# STM32F7x7 register map
File version: 1.4
CPU: CM7 r0p1, little endian, MPU, FPU, VTOR, 4 interrupt priority bits
Registers are 32-bit, read-write, reset 0x0 unless marked. A register's access mark holds for its fields unless they carry their own. Offsets are from the block's base; [hi:lo] are bit positions; lines under a group give offsets from that group; {n}, {i} and the like mark numbered series.

## DFSDM — Digital filter for sigma delta modulators
Base 0x40017400
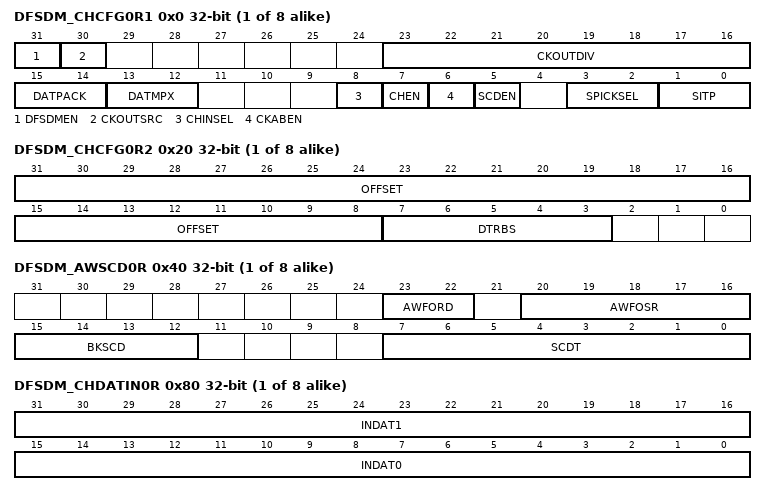
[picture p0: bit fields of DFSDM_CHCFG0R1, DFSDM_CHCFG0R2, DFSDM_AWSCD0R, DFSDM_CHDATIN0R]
{0x0+4i} DFSDM_CHCFG{i}R1 (i=0..7) — DFSDM channel configuration {i} register 1
  [31] DFSDMEN — Global enable for DFSDM interface
  [30] CKOUTSRC — Output serial clock source selection
  [23:16] CKOUTDIV — Output serial clock divider
  [15:14] DATPACK — Data packing mode in DFSDM_CHDATINyR register
  [13:12] DATMPX — Input data multiplexer for channel {i}
  [8] CHINSEL — Channel inputs selection
  [7] CHEN — Channel {i} enable
  [6] CKABEN — Clock absence detector enable on channel {i}
  [5] SCDEN — Short-circuit detector enable on channel {i}
  [3:2] SPICKSEL — SPI clock select for channel {i}
  [1:0] SITP — Serial interface type for channel {i}
{0x20+4i} DFSDM_CHCFG{i}R2 (i=0..7) — DFSDM channel configuration {i} register 2
  [31:8] OFFSET — 24-bit calibration offset for channel {i}
  [7:3] DTRBS — Data right bit-shift for channel {i}
{0x40+4i} DFSDM_AWSCD{i}R (i=0..7) — DFSDM analog watchdog and short-circuit detector register
  [23:22] AWFORD — Analog watchdog Sinc filter order on channel {i}
  [20:16] AWFOSR — Analog watchdog filter oversampling ratio (decimation rate) on channel {i}
  [15:12] BKSCD — Break signal assignment for short-circuit detector on channel {i}
  [7:0] SCDT — short-circuit detector threshold for channel {i}
{0x60+4i} DFSDM_CHWDAT{i}R ro (i=0..7) — DFSDM channel watchdog filter data register
  [15:0] WDATA — Input channel y watchdog data
{0x80+4i} DFSDM_CHDATIN{i}R (i=0..7) — DFSDM channel data input register
  [31:16] INDAT1 — Input data for channel {i+1}
  [15:0] INDAT0 — Input data for channel {i}
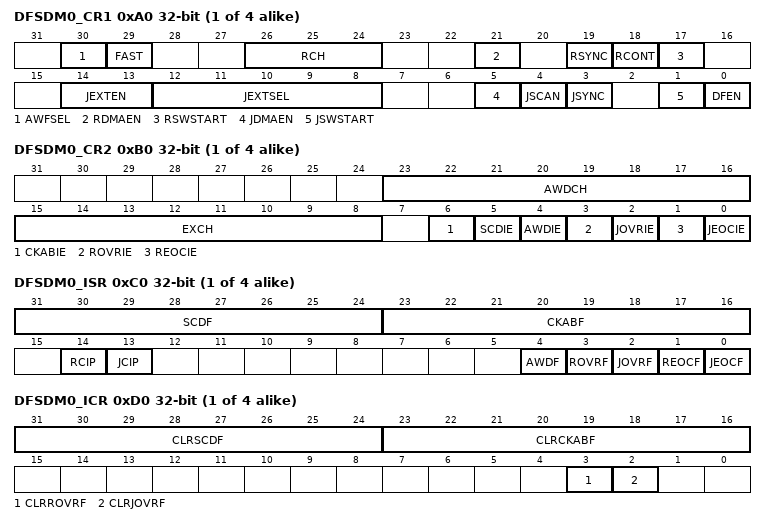
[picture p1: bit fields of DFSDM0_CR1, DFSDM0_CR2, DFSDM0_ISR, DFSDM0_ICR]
{0xA0+4i} DFSDM{i}_CR1 (i=0..3) — DFSDM control register 1
  [30] AWFSEL — Analog watchdog fast mode select
  [29] FAST — Fast conversion mode selection for regular conversions
  [26:24] RCH — Regular channel selection
  [21] RDMAEN — DMA channel enabled to read data for the regular conversion
  [19] RSYNC — Launch regular conversion synchronously with DFSDM0
  [18] RCONT — Continuous mode selection for regular conversions
  [17] RSWSTART — Software start of a conversion on the regular channel
  [14:13] JEXTEN — Trigger enable and trigger edge selection for injected conversions
  [12:8] JEXTSEL — Trigger signal selection for launching injected conversions
  [5] JDMAEN — DMA channel enabled to read data for the injected channel group
  [4] JSCAN — Scanning conversion mode for injected conversions
  [3] JSYNC — Launch an injected conversion synchronously with the DFSDM0 JSWSTART trigger
  [1] JSWSTART — Start a conversion of the injected group of channels
  [0] DFEN — DFSDM enable
{0xB0+4i} DFSDM{i}_CR2 (i=0..3) — DFSDM control register 2
  [23:16] AWDCH — Analog watchdog channel selection
  [15:8] EXCH — Extremes detector channel selection
  [6] CKABIE — Clock absence interrupt enable
  [5] SCDIE — Short-circuit detector interrupt enable
  [4] AWDIE — Analog watchdog interrupt enable
  [3] ROVRIE — Regular data overrun interrupt enable
  [2] JOVRIE — Injected data overrun interrupt enable
  [1] REOCIE — Regular end of conversion interrupt enable
  [0] JEOCIE — Injected end of conversion interrupt enable
{0xC0+4i} DFSDM{i}_ISR ro (i=0..3) — DFSDM interrupt and status register
  [31:24] SCDF — short-circuit detector flag
  [23:16] CKABF — Clock absence flag
  [14] RCIP — Regular conversion in progress status
  [13] JCIP — Injected conversion in progress status
  [4] AWDF — Analog watchdog
  [3] ROVRF — Regular conversion overrun flag
  [2] JOVRF — Injected conversion overrun flag
  [1] REOCF — End of regular conversion flag
  [0] JEOCF — End of injected conversion flag
{0xD0+4i} DFSDM{i}_ICR (i=0..3) — DFSDM interrupt flag clear register
  [31:24] CLRSCDF — Clear the short-circuit detector flag
  [23:16] CLRCKABF — Clear the clock absence flag
  [3] CLRROVRF — Clear the regular conversion overrun flag
  [2] CLRJOVRF — Clear the injected conversion overrun flag
{0xE0+4i} DFSDM{i}_JCHGR (i=0..3) — DFSDM injected channel group selection register
  [7:0] JCHG — Injected channel group selection
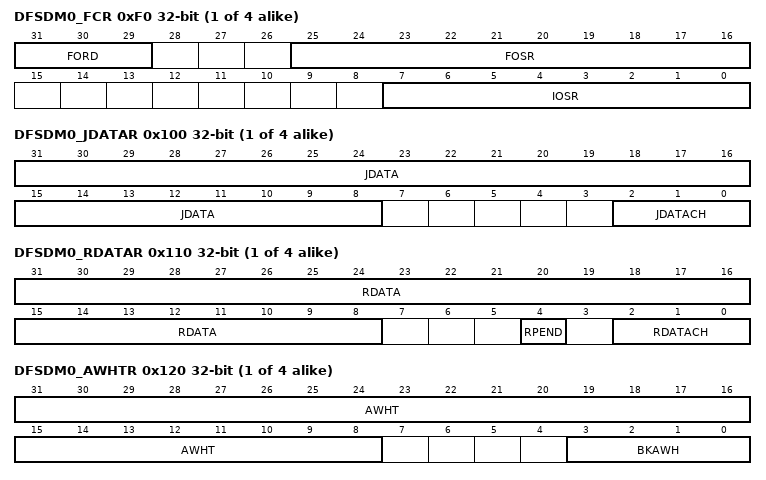
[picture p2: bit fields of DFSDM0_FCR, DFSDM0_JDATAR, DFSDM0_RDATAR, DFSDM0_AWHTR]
{0xF0+4i} DFSDM{i}_FCR (i=0..3) — DFSDM filter control register
  [31:29] FORD — Sinc filter order
  [25:16] FOSR — Sinc filter oversampling ratio (decimation rate)
  [7:0] IOSR — Integrator oversampling ratio (averaging length)
{0x100+4i} DFSDM{i}_JDATAR ro (i=0..3) — DFSDM data register for injected group
  [31:8] JDATA — Injected group conversion data
  [2:0] JDATACH — Injected channel most recently converted
{0x110+4i} DFSDM{i}_RDATAR ro (i=0..3) — DFSDM data register for the regular channel
  [31:8] RDATA — Regular channel conversion data
  [4] RPEND — Regular channel pending data
  [2:0] RDATACH — Regular channel most recently converted
{0x120+4i} DFSDM{i}_AWHTR (i=0..3) — DFSDM analog watchdog high threshold register
  [31:8] AWHT — Analog watchdog high threshold
  [3:0] BKAWH — Break signal assignment to analog watchdog high threshold event
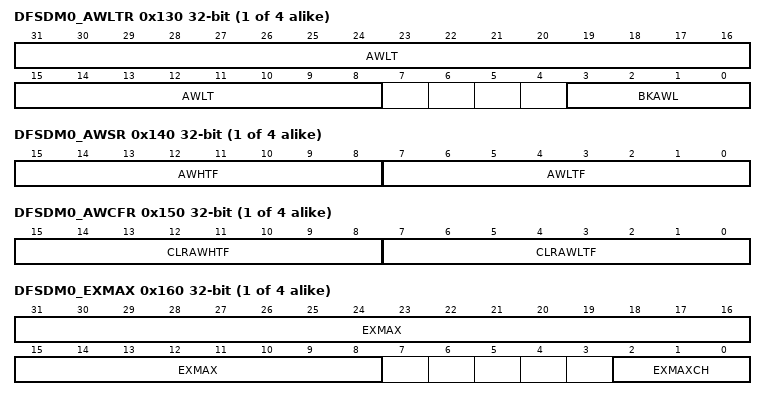
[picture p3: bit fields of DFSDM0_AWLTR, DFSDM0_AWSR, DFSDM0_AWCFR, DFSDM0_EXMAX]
{0x130+4i} DFSDM{i}_AWLTR (i=0..3) — DFSDM analog watchdog low threshold register
  [31:8] AWLT — Analog watchdog low threshold
  [3:0] BKAWL — Break signal assignment to analog watchdog low threshold event
{0x140+4i} DFSDM{i}_AWSR ro (i=0..3) — DFSDM analog watchdog status register
  [15:8] AWHTF — Analog watchdog high threshold flag
  [7:0] AWLTF — Analog watchdog low threshold flag
{0x150+4i} DFSDM{i}_AWCFR (i=0..3) — DFSDM analog watchdog clear flag register
  [15:8] CLRAWHTF — Clear the analog watchdog high threshold flag
  [7:0] CLRAWLTF — Clear the analog watchdog low threshold flag
{0x160+4i} DFSDM{i}_EXMAX ro (i=0..3) — DFSDM Extremes detector maximum register
  [31:8] EXMAX — Extremes detector maximum value
  [2:0] EXMAXCH — Extremes detector maximum data channel
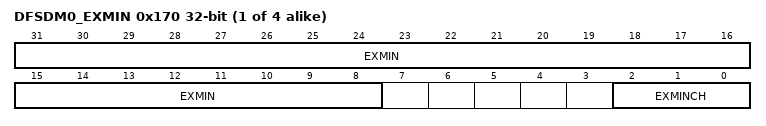
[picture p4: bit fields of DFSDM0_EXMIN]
{0x170+4i} DFSDM{i}_EXMIN ro (i=0..3) — DFSDM Extremes detector minimum register
  [31:8] EXMIN — Extremes detector minimum value
  [2:0] EXMINCH — Extremes detector minimum data channel
{0x180+4i} DFSDM{i}_CNVTIMR ro (i=0..3) — DFSDM conversion timer register
  [31:4] CNVCNT — 28-bit timer counting conversion time
